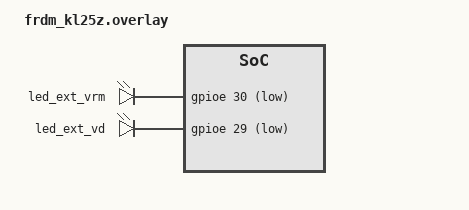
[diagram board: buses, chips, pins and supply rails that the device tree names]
/ {
    aliases {
        led_ext_vrm = &led_ext_vrm;
        led_ext_vd = &led_ext_vd;
    };

    leds {
        compatible = "gpio-leds";

        led_ext_vrm: led_ext_vd {
            gpios = <&gpioe 30 GPIO_ACTIVE_LOW>;
        };

        led_ext_vd: led_ext_vd {
            gpios = <&gpioe 29 GPIO_ACTIVE_LOW>;
        };
    };
};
